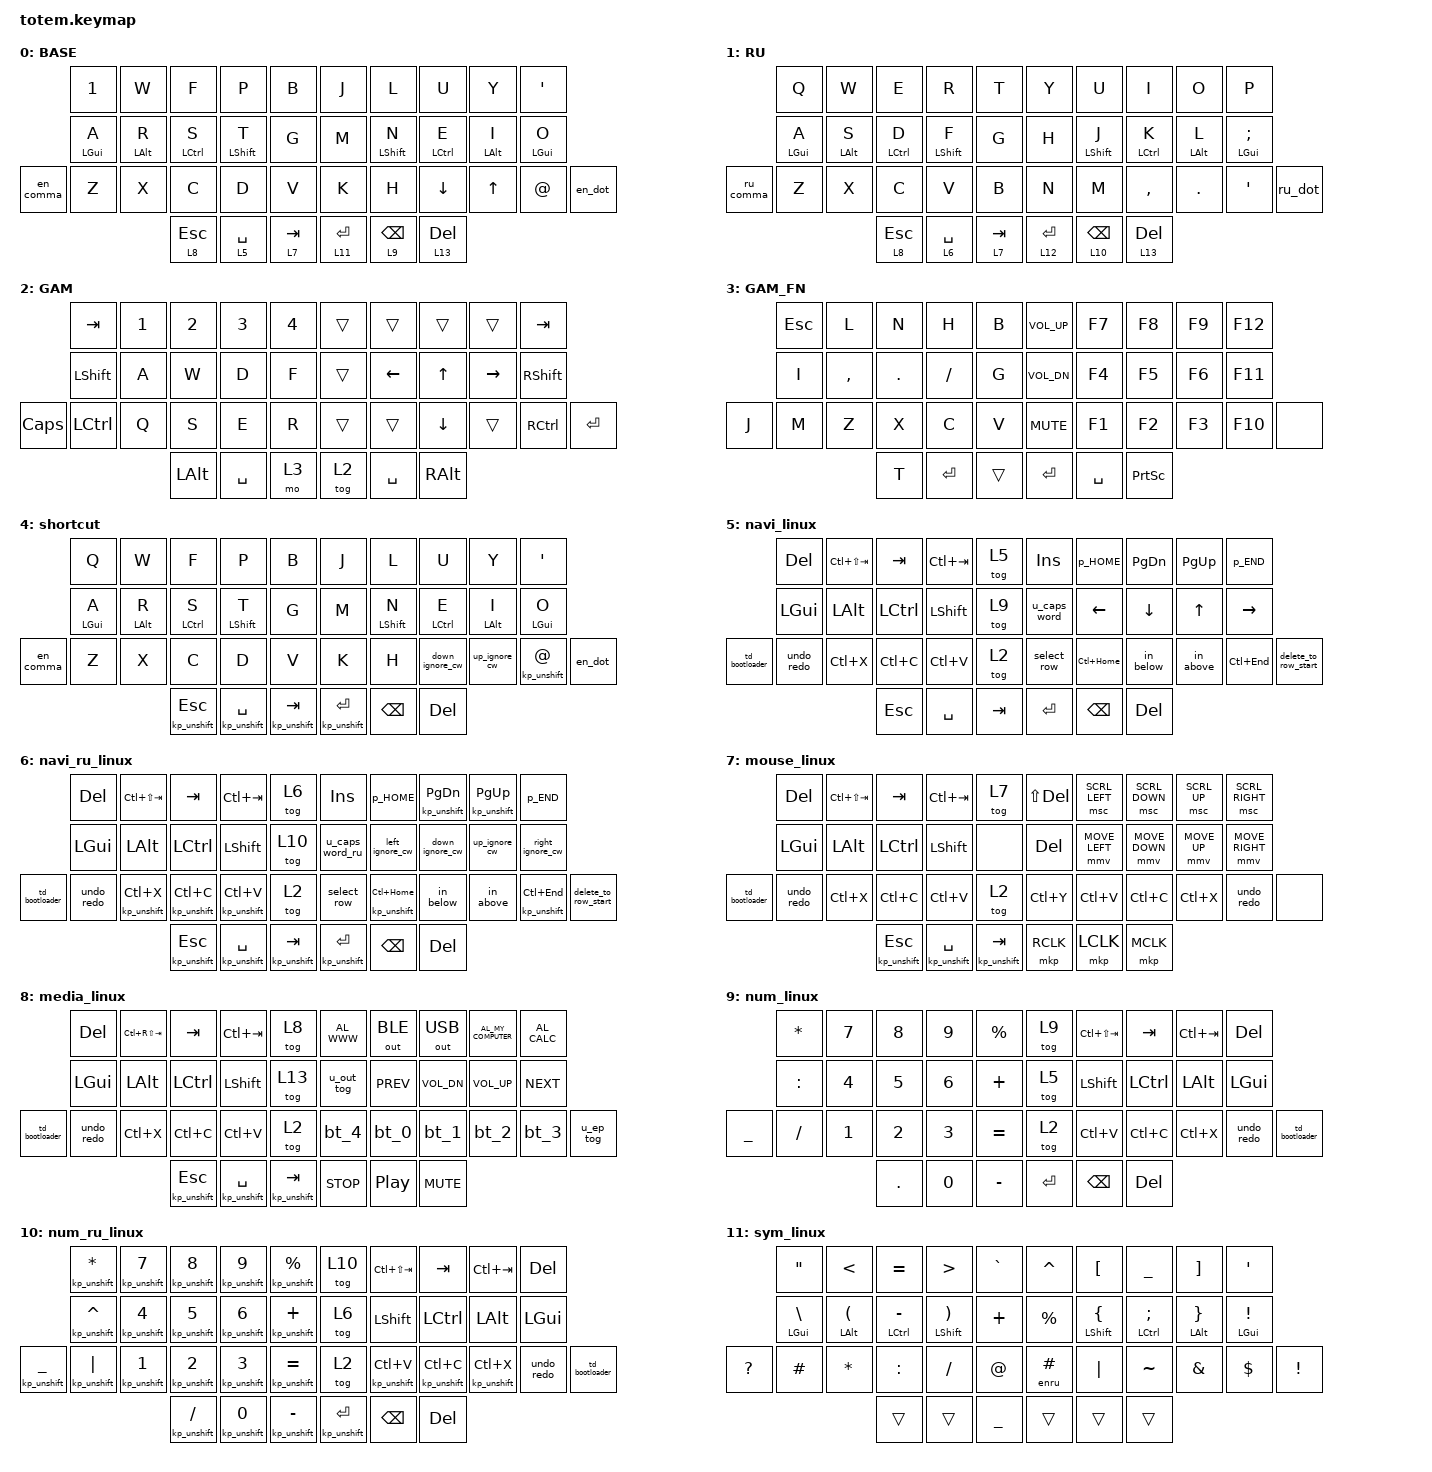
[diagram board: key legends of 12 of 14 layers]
//
//                                                        ▀▀▀▀▀     ▀▀▀▀▀          ▀▀█▀▀
//                                                        ▄▀▀▀▄  ▄  ▄▀▀▀▄  ▄  ▄▀▀▀▄  █  ▄▀▀▀▄
//                                                        █   █  █  █   █  █  █   █  █  █   █
//                                                         ▀▀▀   █   ▀▀▀   █   ▀▀▀   ▀   ▀▀▀
//                                                               █      ▄▄▄█▄▄▄    █   █  
//                                                               ▀      █  █  █     █▄█
//                                                             ▀▀▀▀▀    █  █  █      ▀
//                                                                      ▀  ▀  ▀
//
// ▄▄▄▄▄▄▄▄▄▄▄▄▄▄▄▄▄▄▄▄▄▄▄▄▄▄▄▄▄▄▄▄▄▄▄▄▄▄▄▄▄▄▄▄▄▄▄▄▄▄▄▄▄▄▄▄▄▄▄▄▄▄▄▄▄▄▄▄▄▄▄▄▄▄▄▄▄▄▄▄▄▄▄▄▄▄▄▄▄▄▄▄▄▄▄▄▄▄▄▄▄▄▄▄▄▄▄▄▄▄▄▄▄▄▄▄▄▄▄▄▄▄▄▄▄▄▄▄▄▄▄▄▄▄▄▄▄▄▄▄▄▄▄▄▄▄▄▄▄

#include <behaviors.dtsi>
#include <dt-bindings/zmk/bt.h>
#include <dt-bindings/zmk/ext_power.h>
#include <dt-bindings/zmk/keys.h>
#include <dt-bindings/zmk/outputs.h>
#include <dt-bindings/zmk/pointing.h>

#define BASE 0
#define NAV  1
#define SYM  2
#define ADJ  3
#define TVP1 4
#define TVP2 5

&mt {
    quick-tap-ms = <100>;
    global-quick-tap;
    flavor = "tap-preferred";
    tapping-term-ms = <170>;
};

/ {
    combos {
        compatible = "zmk,combos";

        kha {
            bindings = <&kp LBKT>;
            key-positions = <7 6>;
            layers = <1>;
        };

        hard_sign {
            bindings = <&kp RBKT>;
            key-positions = <7 8>;
            layers = <1>;
        };

        combo_tag_open {
            bindings = <&tag_open>;
            key-positions = <3 1>;
            layers = <11 9>;
        };

        combo_tag_open_ru {
            bindings = <&tag_open_ru>;
            key-positions = <3 1>;
            layers = <12 10>;
        };

        combo_paraphesis_pair {
            bindings = <&paraphesis_pair>;
            key-positions = <13 11>;
            layers = <9 10 11 12>;
        };

        yo {
            bindings = <&kp GRAVE>;
            key-positions = <1 2>;
            layers = <1>;
        };

        combo_en {
            bindings = <&switch_en>;
            key-positions = <23 24>;
            layers = <0 1>;
        };

        combo_ru {
            bindings = <&switch_ru>;
            key-positions = <27 28>;
            layers = <0 1>;
        };

        combo_en_tablet {
            bindings = <&switch_en_tablet>;
            key-positions = <22 24>;
            layers = <0 1>;
        };

        combo_ru_tablet {
            bindings = <&switch_ru_tablet>;
            key-positions = <27 29>;
            layers = <0 1>;
        };
    };

    macros {
        lg_en: lg_en {
            compatible = "zmk,behavior-macro";
            #binding-cells = <0>;
            bindings = <&kp_unshift LC(LS(N8))>;
            label = "LG_EN";
        };

        lg_ru: lg_ru {
            compatible = "zmk,behavior-macro";
            #binding-cells = <0>;
            bindings = <&kp_unshift LC(LS(N9))>;
            label = "LG_RU";
        };

        switch_en: switch_en {
            compatible = "zmk,behavior-macro";
            #binding-cells = <0>;
            bindings = <&to 0 &lg_en>;
            label = "SWITCH_EN";
        };

        switch_ru: switch_ru {
            compatible = "zmk,behavior-macro";
            #binding-cells = <0>;
            bindings = <&to 1 &lg_ru>;
            label = "SWITCH_RU";
        };

        ml: ml {
            compatible = "zmk,behavior-macro-one-param";
            #binding-cells = <1>;
            bindings =
                <&macro_param_1to1 &key_on MACRO_PLACEHOLDER &layer_on 4>,
                <&macro_pause_for_release>,
                <&macro_param_1to1 &key_off MACRO_PLACEHOLDER &layer_off 4>;

            label = "ML";
            wait-ms = <0>;
            tap-ms = <0>;
        };

        ruen: ruen {
            compatible = "zmk,behavior-macro-one-param";
            #binding-cells = <1>;
            bindings = <&lg_en &macro_param_1to1 &kp MACRO_PLACEHOLDER &lg_ru>;
            label = "RUEN";
        };

        enru: enru {
            compatible = "zmk,behavior-macro-one-param";
            #binding-cells = <1>;
            bindings = <&lg_ru &macro_param_1to1 &kp MACRO_PLACEHOLDER &lg_en>;
            label = "ENRU";
        };

        tag_open: tag_open {
            compatible = "zmk,behavior-macro";
            #binding-cells = <0>;
            bindings = <&kp LT &kp GT &kp LEFT>;
            label = "TAG_OPEN";
        };

        tag_open_ru: tag_open_ru {
            compatible = "zmk,behavior-macro";
            #binding-cells = <0>;
            bindings = <&lg_en &kp_unshift LT &kp GT &kp LEFT &lg_ru>;
            label = "TAG_OPEN_RU";
        };

        tag_close: tag_close {
            compatible = "zmk,behavior-macro";
            #binding-cells = <0>;
            bindings = <&kp LT &kp FSLH &kp GT &kp LEFT>;
            label = "TAG_CLOSE";
        };

        tag_close_ru: tag_close_ru {
            compatible = "zmk,behavior-macro";
            #binding-cells = <0>;
            bindings = <&lg_en &kp_unshift LT &kp FSLH &kp GT &kp LEFT &lg_ru>;
            label = "TAG_CLOSE_RU";
        };

        paraphesis_pair: paraphesis_pair {
            compatible = "zmk,behavior-macro";
            #binding-cells = <0>;
            bindings = <&kp_unshift LPAR &kp RPAR &kp LEFT>;
            label = "PARAPHESIS_PAIR";
        };

        bracket_pair: bracket_pair {
            compatible = "zmk,behavior-macro";
            #binding-cells = <0>;
            bindings = <&kp LBKT &kp RBKT &kp LEFT>;
            label = "BRACKET_PAIR";
        };

        bracket_pair_ru: bracket_pair_ru {
            compatible = "zmk,behavior-macro";
            #binding-cells = <0>;
            bindings = <&lg_en &kp_unshift LBKT &kp RBKT &kp LEFT &lg_ru>;
            label = "BRACKET_PAIR_RU";
        };

        braces_pair: braces_pair {
            compatible = "zmk,behavior-macro";
            #binding-cells = <0>;
            bindings = <&kp LBRC &kp RBRC &kp LEFT>;
            label = "BRACES_PAIR";
        };

        braces_pair_ru: braces_pair_ru {
            compatible = "zmk,behavior-macro";
            #binding-cells = <0>;
            bindings = <&lg_en &kp_unshift LBRC &kp RBRC &kp LEFT &lg_ru>;
            label = "BRACES_PAIR_RU";
        };

        bt_clear_0: bt_clear_0 {
            compatible = "zmk,behavior-macro";
            #binding-cells = <0>;
            bindings = <&bt BT_SEL 0 &bt BT_CLR>;
            label = "BT_CLEAR_0";
        };

        bt_clear_1: bt_clear_1 {
            compatible = "zmk,behavior-macro";
            #binding-cells = <0>;
            bindings = <&bt BT_SEL 1 &bt BT_CLR>;
            label = "BT_CLEAR_1";
        };

        bt_clear_2: bt_clear_2 {
            compatible = "zmk,behavior-macro";
            #binding-cells = <0>;
            bindings = <&bt BT_SEL 2 &bt BT_CLR>;
            label = "BT_CLEAR_2";
        };

        bt_clear_3: bt_clear_3 {
            compatible = "zmk,behavior-macro";
            #binding-cells = <0>;
            bindings = <&bt BT_SEL 3 &bt BT_CLR>;
            label = "BT_CLEAR_3";
        };

        bt_clear_4: bt_clear_4 {
            compatible = "zmk,behavior-macro";
            #binding-cells = <0>;
            bindings = <&bt BT_SEL 4 &bt BT_CLR>;
            label = "BT_CLEAR_4";
        };

        in_below: in_below {
            compatible = "zmk,behavior-macro";
            #binding-cells = <0>;
            bindings = <&kp_unshift END &kp LS(RET)>;
            label = "IN_BELOW";
        };

        in_above: in_above {
            compatible = "zmk,behavior-macro";
            #binding-cells = <0>;
            bindings = <&kp_unshift HOME &kp LS(RET) &kp UP>;
            label = "IN_ABOVE";
            wait-ms = <0>;
        };

        rshift_down: rshift_down {
            compatible = "zmk,behavior-macro";
            #binding-cells = <0>;
            bindings = <&macro_press>, <&kp RSHFT>;

            label = "RSHIFT_DOWN";
        };

        kp_unshift: kp_rsup {
            compatible = "zmk,behavior-macro-one-param";
            #binding-cells = <1>;
            bindings =
                <&macro_release>,
                <&kp RSHFT>,
                <&macro_tap>,
                <&macro_param_1to1 &kp MACRO_PLACEHOLDER>;

            label = "KP_RSUP";
            wait-ms = <0>;
            tap-ms = <0>;
        };

        switch_en_tablet: switch_en_tablet {
            compatible = "zmk,behavior-macro";
            #binding-cells = <0>;
            bindings = <&to 0 &kp LC(SPACE)>;
            label = "SWITCH_EN_TABLET";
        };

        switch_ru_tablet: switch_ru_tablet {
            compatible = "zmk,behavior-macro";
            #binding-cells = <0>;
            bindings = <&to 1 &kp LC(SPACE)>;
            label = "SWITCH_RU_TABLET";
        };

        delete_to_row_start: delete_to_row_start {
            compatible = "zmk,behavior-macro";
            #binding-cells = <0>;
            bindings = <&kp LS(HOME) &kp BSPC>;
            label = "DELETE_TO_ROW_START";
        };

        select_row: select_row {
            compatible = "zmk,behavior-macro";
            #binding-cells = <0>;
            bindings = <&kp HOME &kp LS(DOWN)>;
            label = "SELECT_ROW";
        };
    };

    behaviors {
        key_on: key_on {
            compatible = "zmk,behavior-key-toggle";
            label = "KEY_ON";
            #binding-cells = <1>;
        };

        key_off: key_off {
            compatible = "zmk,behavior-key-toggle";
            label = "KEY_OFF";
            #binding-cells = <1>;
            toggle-mode = "off";
        };

        layer_on: layer_on {
            compatible = "zmk,behavior-toggle-layer";
            label = "LAYER_ON";
            #binding-cells = <1>;
        };

        layer_off: layer_off {
            compatible = "zmk,behavior-toggle-layer";
            label = "LAYER_OFF";
            #binding-cells = <1>;
            toggle-mode = "off";
        };

        hrml: hrml {
            compatible = "zmk,behavior-hold-tap";
            label = "HRML";
            bindings = <&ml>, <&kp>;

            #binding-cells = <2>;
            tapping-term-ms = <170>;
            quick-tap-ms = <100>;
            flavor = "tap-preferred";
        };

        td_bootloader: td_bootloader {
            compatible = "zmk,behavior-tap-dance";
            label = "TD_BOOTLOADER";
            #binding-cells = <0>;
            bindings = <&none>, <&bootloader>;
        };

        ru_dot: ru_dot {
            compatible = "zmk,behavior-mod-morph";
            label = "RU_DOT";
            bindings = <&kp_unshift FSLH>, <&kp_unshift EXCL>;

            #binding-cells = <0>;
            mods = <(MOD_LSFT)>;
        };

        ru_comma: ru_comma {
            compatible = "zmk,behavior-mod-morph";
            label = "RU_COMMA";
            bindings = <&kp_unshift QUESTION>, <&kp AMPS>;

            #binding-cells = <0>;
            mods = <(MOD_LSFT)>;
        };

        bt_0: bt_0 {
            compatible = "zmk,behavior-mod-morph";
            label = "BT_0";
            bindings = <&bt BT_SEL 0>, <&bt_clear_0>;

            #binding-cells = <0>;
            mods = <(MOD_LSFT)>;
        };

        bt_1: bt_1 {
            compatible = "zmk,behavior-mod-morph";
            label = "BT_1";
            bindings = <&bt BT_SEL 1>, <&bt_clear_1>;

            #binding-cells = <0>;
            mods = <(MOD_LSFT)>;
        };

        bt_2: bt_2 {
            compatible = "zmk,behavior-mod-morph";
            label = "BT_2";
            bindings = <&bt BT_SEL 2>, <&bt_clear_2>;

            #binding-cells = <0>;
            mods = <(MOD_LSFT)>;
        };

        bt_3: bt_3 {
            compatible = "zmk,behavior-mod-morph";
            label = "BT_3";
            bindings = <&bt BT_SEL 3>, <&bt_clear_3>;

            #binding-cells = <0>;
            mods = <(MOD_LSFT)>;
        };

        bt_4: bt_4 {
            compatible = "zmk,behavior-mod-morph";
            label = "BT_4";
            bindings = <&bt BT_SEL 4>, <&bt_clear_4>;

            #binding-cells = <0>;
            mods = <(MOD_LSFT)>;
        };

        u_out_tog: u_out_tog {
            compatible = "zmk,behavior-mod-morph";
            label = "U_OUT_TOG";
            bindings = <&out OUT_TOG>, <&out OUT_USB>;

            #binding-cells = <0>;
            mods = <(MOD_LSFT)>;
        };

        u_ep_tog: u_ep_tog {
            compatible = "zmk,behavior-mod-morph";
            label = "U_EP_TOG";
            bindings = <&ext_power EP_TOG>, <&ext_power EP_OFF>;

            #binding-cells = <0>;
            mods = <(MOD_LSFT)>;
        };

        u_caps_word: u_caps_word {
            compatible = "zmk,behavior-mod-morph";
            label = "U_CAPS_WORD";
            bindings = <&caps_word>, <&kp CAPS>;

            #binding-cells = <0>;
            mods = <(MOD_LSFT)>;
        };

        u_caps_word_ru: u_caps_word_ru {
            compatible = "zmk,behavior-mod-morph";
            label = "U_CAPS_WORD_RU";
            bindings = <&rshift_down>, <&kp CAPS>;

            #binding-cells = <0>;
            mods = <(MOD_LSFT)>;
        };

        mt_ruen: mt_ruen {
            compatible = "zmk,behavior-hold-tap";
            label = "MT_RUEN";
            #binding-cells = <2>;
            bindings = <&kp>, <&ruen>;

            quick-tap-ms = <100>;
            global-quick-tap;
            flavor = "tap-preferred";
            tapping-term-ms = <170>;
        };

        undo_redo: undo_redo {
            compatible = "zmk,behavior-mod-morph";
            label = "UNDO_REDO";
            bindings = <&kp_unshift LC(Z)>, <&kp_unshift LC(Y)>;

            #binding-cells = <0>;
            mods = <(MOD_LSFT)>;
        };

        p_HOME: p_HOME {
            compatible = "zmk,behavior-mod-morph";
            label = "P_HOME";
            bindings = <&kp_unshift HOME>, <&kp_unshift HOME>;

            #binding-cells = <0>;
            mods = <(MOD_LCTL)>;
        };

        p_END: p_END {
            compatible = "zmk,behavior-mod-morph";
            label = "P_END";
            bindings = <&kp_unshift END>, <&kp_unshift END>;

            #binding-cells = <0>;
            mods = <(MOD_LCTL)>;
        };

        lt_unshift: lt_unshift {
            compatible = "zmk,behavior-hold-tap";
            label = "LT_UNSHIFT";
            #binding-cells = <2>;
            tapping-term-ms = <170>;
            flavor = "balanced";
            bindings = <&mo>, <&kp_unshift>;
        };

        up_ignore_cw: up_ignore_cw {
            compatible = "zmk,behavior-mod-morph";
            label = "UP_IGNORE_CW";
            bindings = <&kp UP>, <&kp UP>;

            #binding-cells = <0>;
            mods = <(MOD_RSFT)>;
        };

        down_ignore_cw: down_ignore_cw {
            compatible = "zmk,behavior-mod-morph";
            label = "DOWN_IGNORE_CW";
            bindings = <&kp DOWN>, <&kp DOWN>;

            #binding-cells = <0>;
            mods = <(MOD_RSFT)>;
        };

        left_ignore_cw: left_ignore_cw {
            compatible = "zmk,behavior-mod-morph";
            label = "LEFT_IGNORE_CW";
            bindings = <&kp LEFT>, <&kp LEFT>;

            #binding-cells = <0>;
            mods = <(MOD_RSFT)>;
        };

        right_ignore_cw: right_ignore_cw {
            compatible = "zmk,behavior-mod-morph";
            label = "RIGHT_IGNORE_CW";
            bindings = <&kp RIGHT>, <&kp RIGHT>;

            #binding-cells = <0>;
            mods = <(MOD_RSFT)>;
        };

        mt_unshift: mt_unshift {
            compatible = "zmk,behavior-hold-tap";
            label = "MT_UNSHIFT";
            #binding-cells = <2>;
            tapping-term-ms = <170>;
            flavor = "tap-preferred";
            bindings = <&kp>, <&kp_unshift>;

            quick-tap-ms = <100>;
        };

        en_dot: en_dot {
            compatible = "zmk,behavior-mod-morph";
            label = "EN_DOT";
            bindings = <&kp_unshift DOT>, <&kp_unshift EXCL>;

            #binding-cells = <0>;
            mods = <(MOD_LSFT)>;
        };

        en_comma: en_comma {
            compatible = "zmk,behavior-mod-morph";
            label = "EN_COMMA";
            bindings = <&kp_unshift COMMA>, <&kp_unshift QMARK>;

            #binding-cells = <0>;
            mods = <(MOD_LSFT)>;
        };
    };

    keymap {
        compatible = "zmk,keymap";

        // ▄▄▄▄▄▄▄▄▄▄▄▄▄▄▄▄▄▄▄▄▄▄▄▄▄▄▄▄▄▄▄▄▄▄▄▄▄▄▄▄▄▄▄▄▄▄▄▄▄▄▄▄▄▄▄▄▄▄▄▄▄▄▄▄▄▄▄▄▄▄▄▄▄▄▄▄▄▄▄▄▄▄▄▄▄▄▄▄▄▄▄▄▄▄▄▄▄▄▄▄▄▄▄▄▄▄▄▄▄▄▄▄▄▄▄▄▄▄▄▄▄▄▄▄▄▄▄▄▄▄▄▄▄▄▄▄▄▄▄▄▄▄▄▄▄▄▄▄▄

        base_layer_linux {
            // ┏━━━━━━━━━━━━━━━━━━━━━━━━━━━━━━━━━━━━━━━┓

            label = "BASE";

            // ┗━━━━━━━━━━━━━━━━━━━━━━━━━━━━━━━━━━━━━━━┛
            //             ┏━━━━━━━━━━━┳━━━━━━━━━━━┳━━━━━━━━━━━┳━━━━━━━━━━━┳━━━━━━━━━━━┓   ┏━━━━━━━━━━━┳━━━━━━━━━━━┳━━━━━━━━━━━┳━━━━━━━━━━━┳━━━━━━━━━━━┓
            //             ┃     Q     ┃     W     ┃     F     ┃     P     ┃     G     ┃   ┃     J     ┃     L     ┃     U     ┃     Y     ┃     ;     ┃
            //             ┣━━━━━━━━━━━╋━━━━━━━━━━━╋━━━━━━━━━━━╋━━━━━━━━━━━╋━━━━━━━━━━━┫   ┣━━━━━━━━━━━╋━━━━━━━━━━━╋━━━━━━━━━━━╋━━━━━━━━━━━╋━━━━━━━━━━━┫
            //             ┃     A     ┃     R     ┃     S     ┃     T     ┃     D     ┃   ┃     H     ┃     N     ┃     E     ┃     I     ┃     O     ┃
            // ┏━━━━━━━━━━━╋━━━━━━━━━━━╋━━━━━━━━━━━╋━━━━━━━━━━━╋━━━━━━━━━━━╋━━━━━━━━━━━┫   ┣━━━━━━━━━━━╋━━━━━━━━━━━╋━━━━━━━━━━━╋━━━━━━━━━━━╋━━━━━━━━━━━╋━━━━━━━━━━━┓
            // ┃     Q     ┃     Z     ┃     X     ┃     C     ┃     V     ┃     B     ┃   ┃     K     ┃     M     ┃     ,     ┃     .     ┃     /     ┃     \     ┃
            // ┗━━━━━━━━━━━┻━━━━━━━━━━━┻━━━━━━━━━━━╋━━━━━━━━━━━╋━━━━━━━━━━━╋━━━━━━━━━━━┫   ┣━━━━━━━━━━━╋━━━━━━━━━━━╋━━━━━━━━━━━╋━━━━━━━━━━━┻━━━━━━━━━━━┻━━━━━━━━━━━┛
            //                                     ┃    DEL    ┃    TAB    ┃    SPC    ┃   ┃   ENTER   ┃           ┃   BSPC    ┃
            //                                     ┗━━━━━━━━━━━┻━━━━━━━━━━━┻━━━━━━━━━━━┛   ┗━━━━━━━━━━━┻━━━━━━━━━━━┻━━━━━━━━━━━┛

            bindings = <
           &kp N1       &kp W       &kp F        &kp P        &kp B        &kp J       &kp L        &kp U        &kp Y       &kp APOS
           &mt LGUI A  &mt LALT R  &mt LCTRL S  &mt LSHFT T  &kp G        &kp M       &mt LSHFT N  &mt LCTRL E  &mt LALT I  &mt LGUI O
&en_comma  &kp Z       &kp X       &kp C        &kp D        &kp V        &kp K       &kp H        &kp DOWN     &kp UP      &kp AT      &en_dot
                                   &lt 8 ESC    &lt 5 SPACE  &lt 7 TAB    &lt 11 RET  &lt 9 BSPC   &lt 13 DEL
            >;
        };

        ru_layer_linux {
            bindings = <
           &kp Q         &kp W         &kp E              &kp R                &kp T                &kp Y               &kp U        &kp I          &kp O         &kp P
           &hrml LGUI A  &hrml LALT S  &hrml LCTRL D      &mt LSHFT F          &kp G                &kp H               &mt LSHFT J  &hrml LCTRL K  &hrml LALT L  &hrml LGUI SEMI
&ru_comma  &kp Z         &kp X         &kp C              &kp V                &kp B                &kp N               &kp M        &kp COMMA      &kp DOT       &kp SQT          &ru_dot
                                       &lt_unshift 8 ESC  &lt_unshift 6 SPACE  &lt_unshift 7 TAB    &lt_unshift 12 RET  &lt 10 BSPC  &lt 13 DEL
            >;

            label = "RU";
        };

        gaming_layer {
            bindings = <
          &kp TAB    &kp N1  &kp N2    &kp N3     &kp N4    &trans  &trans     &trans    &trans     &kp TAB
          &kp LSHFT  &kp A   &kp W     &kp D      &kp F     &trans  &kp LEFT   &kp UP    &kp RIGHT  &kp RSHFT
&kp CAPS  &kp LCTRL  &kp Q   &kp S     &kp E      &kp R     &trans  &trans     &kp DOWN  &trans     &kp RCTRL  &kp RET
                             &kp LALT  &kp SPACE  &mo 3     &tog 2  &kp SPACE  &kp RALT
            >;

            label = "GAM";
        };

        gaming_fn {
            bindings = <
       &kp ESC  &kp L      &kp N    &kp H     &kp B     &kp C_VOL_UP  &kp F7     &kp F8     &kp F9  &kp F12
       &kp I    &kp COMMA  &kp DOT  &kp FSLH  &kp G     &kp C_VOL_DN  &kp F4     &kp F5     &kp F6  &kp F11
&kp J  &kp M    &kp Z      &kp X    &kp C     &kp V     &kp K_MUTE    &kp F1     &kp F2     &kp F3  &kp F10  &none
                           &kp T    &kp RET   &trans    &kp RET       &kp SPACE  &kp PSCRN
            >;

            label = "GAM_FN";
        };

        shortcut_linux {
            label = "shortcut";
            bindings = <
           &kp Q       &kp W       &kp F            &kp P              &kp B              &kp J              &kp L        &kp U            &kp Y          &kp APOS
           &mt LGUI A  &mt LALT R  &mt LCTRL S      &mt LSHFT T        &kp G              &kp M              &mt LSHFT N  &mt LCTRL E      &mt LALT I     &mt LGUI O
&en_comma  &kp Z       &kp X       &kp C            &kp D              &kp V              &kp K              &kp H        &down_ignore_cw  &up_ignore_cw  &kp_unshift AT  &en_dot
                                   &kp_unshift ESC  &kp_unshift SPACE  &kp_unshift TAB    &kp_unshift ENTER  &kp BSPC     &kp DEL
            >;
        };

        navi_linux {
            bindings = <
                &kp DEL     &kp LC(LS(TAB))  &kp TAB    &kp LC(TAB)  &tog 5     &kp INS       &p_HOME       &kp PG_DN  &kp PG_UP  &p_END
                &kp LGUI    &kp LALT         &kp LCTRL  &kp LSHFT    &tog 9     &u_caps_word  &kp LEFT      &kp DOWN   &kp UP     &kp RIGHT
&td_bootloader  &undo_redo  &kp LC(X)        &kp LC(C)  &kp LC(V)    &tog 2     &select_row   &kp LC(HOME)  &in_below  &in_above  &kp LC(END)  &delete_to_row_start
                                             &kp ESC    &kp SPACE    &kp TAB    &kp RET       &kp BSPC      &kp DEL
            >;
        };

        navi_ru_linux {
            bindings = <
                &kp DEL     &kp LC(LS(TAB))    &kp TAB            &kp LC(TAB)        &tog 6             &kp INS          &p_HOME               &kp_unshift PG_DN  &kp_unshift PG_UP  &p_END
                &kp LGUI    &kp LALT           &kp LCTRL          &kp LSHFT          &tog 10            &u_caps_word_ru  &left_ignore_cw       &down_ignore_cw    &up_ignore_cw      &right_ignore_cw
&td_bootloader  &undo_redo  &kp_unshift LC(X)  &kp_unshift LC(C)  &kp_unshift LC(V)  &tog 2             &select_row      &kp_unshift LC(HOME)  &in_below          &in_above          &kp_unshift LC(END)  &delete_to_row_start
                                               &kp_unshift ESC    &kp_unshift SPACE  &kp_unshift TAB    &kp_unshift RET  &kp BSPC              &kp DEL
            >;
        };

        mouse_linux {
            bindings = <
                &kp DEL     &kp LC(LS(TAB))  &kp TAB          &kp LC(TAB)        &tog 7             &kp LS(DEL)  &msc SCRL_LEFT  &msc SCRL_DOWN  &msc SCRL_UP  &msc SCRL_RIGHT
                &kp LGUI    &kp LALT         &kp LCTRL        &kp LSHFT          &none              &kp DEL      &mmv MOVE_LEFT  &mmv MOVE_DOWN  &mmv MOVE_UP  &mmv MOVE_RIGHT
&td_bootloader  &undo_redo  &kp LC(X)        &kp LC(C)        &kp LC(V)          &tog 2             &kp LC(Y)    &kp LC(V)       &kp LC(C)       &kp LC(X)     &undo_redo       &none
                                             &kp_unshift ESC  &kp_unshift SPACE  &kp_unshift TAB    &mkp RCLK    &mkp LCLK       &mkp MCLK
            >;
        };

        media_linux {
            bindings = <
                &kp DEL     &kp LC(RS(TAB))  &kp TAB          &kp LC(TAB)        &tog 8             &kp C_AL_WWW  &out OUT_BLE  &out OUT_USB  &kp C_AL_MY_COMPUTER  &kp C_AL_CALC
                &kp LGUI    &kp LALT         &kp LCTRL        &kp LSHFT          &tog 13            &u_out_tog    &kp C_PREV    &kp C_VOL_DN  &kp C_VOL_UP          &kp C_NEXT
&td_bootloader  &undo_redo  &kp LC(X)        &kp LC(C)        &kp LC(V)          &tog 2             &bt_4         &bt_0         &bt_1         &bt_2                 &bt_3          &u_ep_tog
                                             &kp_unshift ESC  &kp_unshift SPACE  &kp_unshift TAB    &kp C_STOP    &kp C_PP      &kp K_MUTE
            >;
        };

        num_linux {
            bindings = <
           &kp STAR   &kp N7  &kp N8   &kp N9  &kp PRCNT    &tog 9     &kp LC(LS(TAB))  &kp TAB    &kp LC(TAB)  &kp DEL
           &kp COLON  &kp N4  &kp N5   &kp N6  &kp PLUS     &tog 5     &kp LSHFT        &kp LCTRL  &kp LALT     &kp LGUI
&kp UNDER  &kp FSLH   &kp N1  &kp N2   &kp N3  &kp EQUAL    &tog 2     &kp LC(V)        &kp LC(C)  &kp LC(X)    &undo_redo  &td_bootloader
                              &kp DOT  &kp N0  &kp MINUS    &kp ENTER  &kp BSPC         &kp DEL
            >;
        };

        num_ru_linux {
            bindings = <
                   &kp_unshift STAR   &kp_unshift N7  &kp_unshift N8    &kp_unshift N9  &kp_unshift PRCNT    &tog 10            &kp LC(LS(TAB))    &kp TAB            &kp LC(TAB)        &kp DEL
                   &kp_unshift CARET  &kp_unshift N4  &kp_unshift N5    &kp_unshift N6  &kp_unshift PLUS     &tog 6             &kp LSHFT          &kp LCTRL          &kp LALT           &kp LGUI
&kp_unshift UNDER  &kp_unshift PIPE   &kp_unshift N1  &kp_unshift N2    &kp_unshift N3  &kp_unshift EQUAL    &tog 2             &kp_unshift LC(V)  &kp_unshift LC(C)  &kp_unshift LC(X)  &undo_redo  &td_bootloader
                                                      &kp_unshift FSLH  &kp_unshift N0  &kp_unshift MINUS    &kp_unshift ENTER  &kp BSPC           &kp DEL
            >;
        };

        sym_linux {
            bindings = <
           &kp DQT        &kp LT         &kp EQUAL        &kp GT          &kp GRAVE    &kp CARET   &kp LBKT        &kp UNDER       &kp RBKT       &kp SQT
           &mt LGUI BSLH  &mt LALT LPAR  &mt LCTRL MINUS  &mt LSHFT RPAR  &kp PLUS     &kp PRCNT   &mt LSHFT LBRC  &mt LCTRL SEMI  &mt LALT RBRC  &mt LGUI EXCL
&kp QMARK  &kp HASH       &kp STAR       &kp COLON        &kp FSLH        &kp AT       &enru HASH  &kp PIPE        &kp TILDE       &kp AMPS       &kp DLLR       &kp EXCL
                                         &trans           &trans          &kp UNDER    &trans      &trans          &trans
            >;
        };

        sym_ru_linux {
            bindings = <
                  &kp_unshift AT         &ruen LT               &kp_unshift EQUAL        &ruen GT                 &ruen GRAVE          &ruen CARET        &ruen LBKT           &kp UNDER               &ruen RBKT          &ruen SQT
                  &mt_unshift LGUI BSLH  &mt_unshift LALT LPAR  &mt_unshift LCTRL MINUS  &mt_unshift LSHIFT RPAR  &kp_unshift PLUS     &kp_unshift PRCNT  &mt_ruen LSHFT LBRC  &mt_unshift LCTRL DLLR  &mt_ruen LALT RBRC  &mt_unshift LGUI EXCL
&kp_unshift AMPS  &ruen HASH             &kp_unshift STAR       &kp_unshift CARET        &kp_unshift PIPE         &ruen AT             &kp_unshift HASH   &ruen PIPE           &ruen TILDE             &ruen AMPS          &ruen DLLR             &kp_unshift EXCL
                                                                &trans                   &trans                   &kp_unshift UNDER    &trans             &trans               &trans
            >;
        };

        fun_linux {
            bindings = <
         &kp F12  &kp F7  &kp F8     &kp F9             &kp PSCRN          &tog 13            &kp LC(LS(TAB))  &kp TAB    &kp LC(TAB)  &kp DEL
         &kp F11  &kp F4  &kp F5     &kp F6             &kp SCROLLLOCK     &tog 8             &kp LSHFT        &kp LCTRL  &kp LALT     &kp LGUI
&kp F13  &kp F10  &kp F1  &kp F2     &kp F3             &kp PAUSE_BREAK    &tog 2             &kp LC(V)        &kp LC(C)  &kp LC(X)    &undo_redo  &td_bootloader
                          &kp K_APP  &kp_unshift SPACE  &kp_unshift TAB    &kp_unshift ENTER  &kp BSPC         &kp DEL
            >;
        };
    };
};
